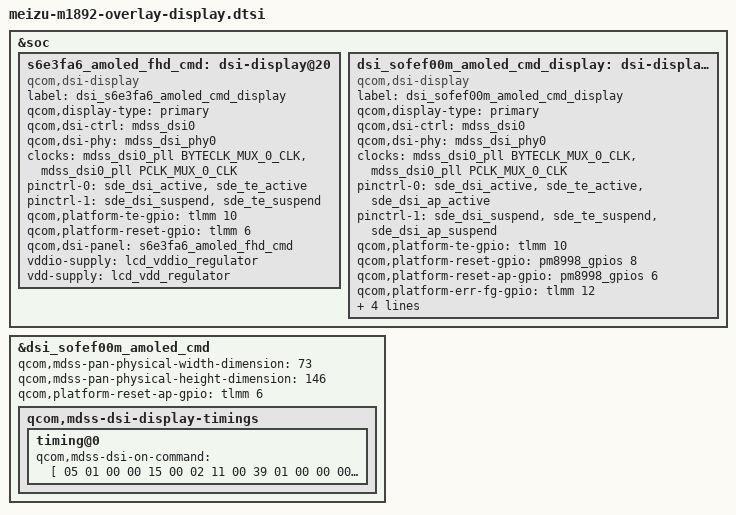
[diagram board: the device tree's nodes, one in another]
#include "dsi-panel-sofef00m-amoled-fhd-cmd.dtsi"
#include "dsi-panel-sofef00m-amoled-fhd-cmd.dtsi"

&soc {
	s6e3fa6_amoled_fhd_cmd: dsi-display@20 {
		compatible = "qcom,dsi-display";
		label = "dsi_s6e3fa6_amoled_cmd_display";
		qcom,display-type = "primary";
		qcom,dsi-ctrl = <&mdss_dsi0>;
		qcom,dsi-phy = <&mdss_dsi_phy0>;
		clocks = <&mdss_dsi0_pll BYTECLK_MUX_0_CLK>,
			<&mdss_dsi0_pll PCLK_MUX_0_CLK>;
		clock-names = "src_byte_clk", "src_pixel_clk";
		pinctrl-names = "panel_active", "panel_suspend";
		pinctrl-0 = <&sde_dsi_active &sde_te_active>;
		pinctrl-1 = <&sde_dsi_suspend &sde_te_suspend>;
		qcom,platform-te-gpio = <&tlmm 10 0>;
		qcom,platform-reset-gpio = <&tlmm 6 0>;
		qcom,dsi-panel = <&s6e3fa6_amoled_fhd_cmd>;
		vddio-supply = <&lcd_vddio_regulator>;
		vdd-supply = <&lcd_vdd_regulator>;
	};

	dsi_sofef00m_amoled_cmd_display: dsi-display@21 {
		compatible = "qcom,dsi-display";
		label = "dsi_sofef00m_amoled_cmd_display";
		qcom,display-type = "primary";
		qcom,dsi-ctrl = <&mdss_dsi0>;
		qcom,dsi-phy = <&mdss_dsi_phy0>;
		clocks = <&mdss_dsi0_pll BYTECLK_MUX_0_CLK>,
			<&mdss_dsi0_pll PCLK_MUX_0_CLK>;
		clock-names = "src_byte_clk", "src_pixel_clk";
		pinctrl-names = "panel_active", "panel_suspend";
		pinctrl-0 = <&sde_dsi_active &sde_te_active>,
			<&sde_dsi_ap_active>;
		pinctrl-1 = <&sde_dsi_suspend &sde_te_suspend>,
			<&sde_dsi_ap_suspend>;
		qcom,platform-te-gpio = <&tlmm 10 0>;
		qcom,platform-reset-gpio = <&pm8998_gpios 8 0>;
		qcom,platform-reset-ap-gpio = <&pm8998_gpios 6 0>;
		qcom,platform-err-fg-gpio = <&tlmm 12 0>;
		qcom,dsi-panel = <&dsi_sofef00m_amoled_cmd>;
		vddio-supply = <&lcd_vddio_regulator>;
		vdd-supply = <&lcd_vdd_regulator>;
		qcom,dsi-display-active;
	};
}:

&dsi_sofef00m_amoled_cmd {
	qcom,mdss-pan-physical-width-dimension = <73>;
	qcom,mdss-pan-physical-height-dimension = <146>;
	qcom,platform-reset-ap-gpio = <&tlmm 6 0>;

	qcom,mdss-dsi-display-timings {
		timing@0 {
			qcom,mdss-dsi-on-command = [
				05 01 00 00 15 00 02 11 00 39 01 00
				00 00 00 03 F0 5A 5A 39 01 00 00 00
				00 03 FC 5A 5A 39 01 00 00 00 00 02
				B0 03 39 01 00 00 00 00 02 D2 9E 39
				01 00 00 00 00 03 F0 A5 A5 39 01 00
				00 00 00 03 FC A5 A5 39 01 00 00 00
				00 03 F0 5A 5A 15 01 00 00 00 00 02
				35 00 39 01 00 00 00 00 03 F0 A5 A5
				39 01 00 00 00 00 05 2B 00 00 08 6F
				39 01 00 00 00 00 03 F0 5A 5A 39 01
				00 00 00 00 02 B0 01 39 01 00 00 00
				00 02 BB 03 39 01 00 00 00 00 02 B0
				03 39 01 00 00 00 00 04 EF 33 31 14
				39 01 00 00 00 00 03 F0 A5 A5 15 01
				00 00 00 00 02 53 28 39 01 00 00 00
				00 03 51 00 00 15 01 00 00 00 00 02
				55 00 39 01 00 00 00 00 03 F0 5A 5A
				39 01 00 00 00 00 03 F0 5A 5A 15 01
				00 00 00 00 02 B0 05 15 01 00 00 00
				00 02 B1 03 39 01 00 00 00 00 03 F0
				A5 A5 15 01 00 00 00 00 02 B0 02 39
				01 00 00 00 00 40 E2 B3 0C 04 39 CE
				13 07 04 AF 44 E6 CD C9 11 C2 EA E6
				18 FF FF FF F1 10 07 00 C0 00 07 05
				B5 00 D7 C0 FF 16 C4 E7 E4 0F FF FF
				FF BD 02 00 0C D6 01 06 04 A5 06 EE
				C9 C8 0A DF D1 E7 06 FF FE FE 39 01
				00 00 00 00 03 F0 A5 A5 39 01 00 00
				00 00 03 F0 5A 5A 15 01 00 00 00 00
				02 B0 01 15 01 00 00 00 00 02 E2 01
				39 01 00 00 00 00 03 F0 A5 A5 39 01
				00 00 00 00 03 F0 5A 5A 15 01 00 00
				00 00 02 B0 02 39 01 00 00 00 00 05
				D5 02 00 14 14 39 01 00 00 6E 00 03
				F0 A5 A5 05 01 00 00 00 00 02 29 00
			];
		};
	};
};
